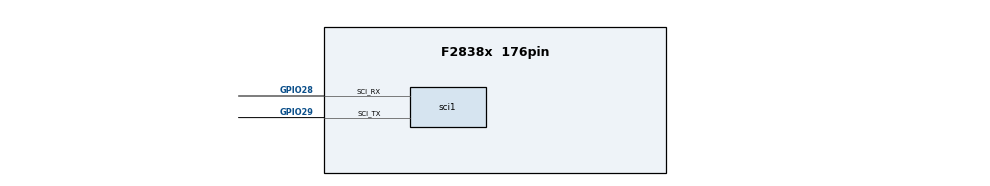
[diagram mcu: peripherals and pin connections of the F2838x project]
/**
 * @cliArgs --device "F2838x" --part "F2838x_176pin" --package "176pin" --context "CPU2" --product "C:/ti/c2000/C2000Ware_26_00_00_00/.metadata/sdk.json"
 * @versions {"tool":"1.27.0+4565"}
 */

/**
 * Import the modules used in this configuration.
 */
const ipc  = scripting.addModule("/driverlib/ipc.js");
const sci  = scripting.addModule("/driverlib/sci.js", {}, false);
const sci1 = sci.addInstance();

/**
 * Write custom configuration values to the imported modules.
 */
ipc.enableInterrupt1        = true;
ipc.ipcRegisterFlag         = ["IPC_FLAG1","IPC_FLAG31"];
ipc.registerInterrupts      = ["0"];
ipc.ipcInt0.enableInterrupt = true;

sci1.$name                 = "mySCI1";
sci1.sci.$assign           = "SCIA";
sci1.sci.sci_rxPin.$assign = "GPIO28";
sci1.sci.sci_txPin.$assign = "GPIO29";
sci1.baudRates             = 115200;
sci1.useInterrupts         = true;
sci1.useFifo               = true;
sci1.selectRegisteredInterrupts = ["registerRxInt"];
sci1.enabledFIFOInterrupts = ["SCI_INT_RXFF"];
sci1.enabledErrorInterrupts = ["SCI_INT_RXERR","SCI_INT_FE","SCI_INT_OE","SCI_INT_PE"];
sci1.rxFifo                 = "SCI_FIFO_RX1";
sci1.txFifo                 = "SCI_FIFO_TX0";
sci1.rxQual.$name          = "myGPIOQUAL0";
sci1.txQual.$name          = "myGPIOQUAL1";
